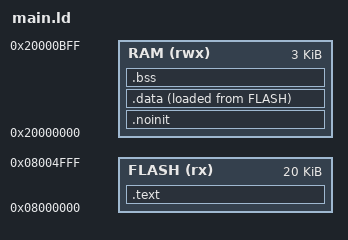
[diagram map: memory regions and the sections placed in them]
/* main.ld - Script de Enlazado Autónomo para Puya PY32F002A */
ENTRY(Reset_Handler)

MEMORY
{
    FLASH (rx)  : ORIGIN = 0x08000000, LENGTH = 20K
    RAM   (rwx) : ORIGIN = 0x20000000, LENGTH = 3K
}

SECTIONS
{
    .text :
    {
        . = ALIGN(4);
        KEEP(*(.isr_vector))
        *(.text*)
        *(.rodata*)
        . = ALIGN(4);
    } > FLASH

    .noinit (NOLOAD) :
    {
        . = ALIGN(4);
        *(.noinit*)
        . = ALIGN(4);
    } > RAM

    _sidata = LOADADDR(.data);
    .data :
    {
        . = ALIGN(4);
        _sdata = .;
        *(.data*)
        . = ALIGN(4);
        _edata = .;
    } > RAM AT > FLASH

    .bss :
    {
        . = ALIGN(4);
        _sbss = .;
        *(.bss*)
        . = ALIGN(4);
        _ebss = .;
    } > RAM

    _estack = ORIGIN(RAM) + LENGTH(RAM);
}
